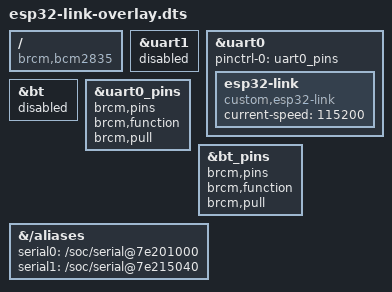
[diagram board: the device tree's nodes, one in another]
/dts-v1/;
/plugin/;

/*
 * Raspberry Pi 3 B+: libera el PL011 (UART0) del Bluetooth integrado,
 * lo asigna a GPIO14/15 (pines fisicos 8/10) y describe al ESP32 como
 * dispositivo hijo serdev. Este overlay reemplaza a dtoverlay=disable-bt.
 */
/ {
	compatible = "brcm,bcm2835";

	fragment@0 {
		target = <&uart1>;
		__overlay__ {
			status = "disabled";
		};
	};

	fragment@1 {
		target = <&uart0>;
		__overlay__ {
			pinctrl-names = "default";
			pinctrl-0 = <&uart0_pins>;
			status = "okay";

			esp32-link {
				compatible = "custom,esp32-link";
				current-speed = <115200>;
				status = "okay";
			};
		};
	};

	fragment@2 {
		target = <&bt>;
		__overlay__ {
			status = "disabled";
		};
	};

	/* GPIO32/33 son los pines internos del Bluetooth, no los del header. */
	fragment@3 {
		target = <&uart0_pins>;
		__overlay__ {
			brcm,pins;
			brcm,function;
			brcm,pull;
		};
	};

	fragment@4 {
		target = <&bt_pins>;
		__overlay__ {
			brcm,pins;
			brcm,function;
			brcm,pull;
		};
	};

	fragment@5 {
		target-path = "/aliases";
		__overlay__ {
			serial0 = "/soc/serial@7e201000";
			serial1 = "/soc/serial@7e215040";
		};
	};
};
